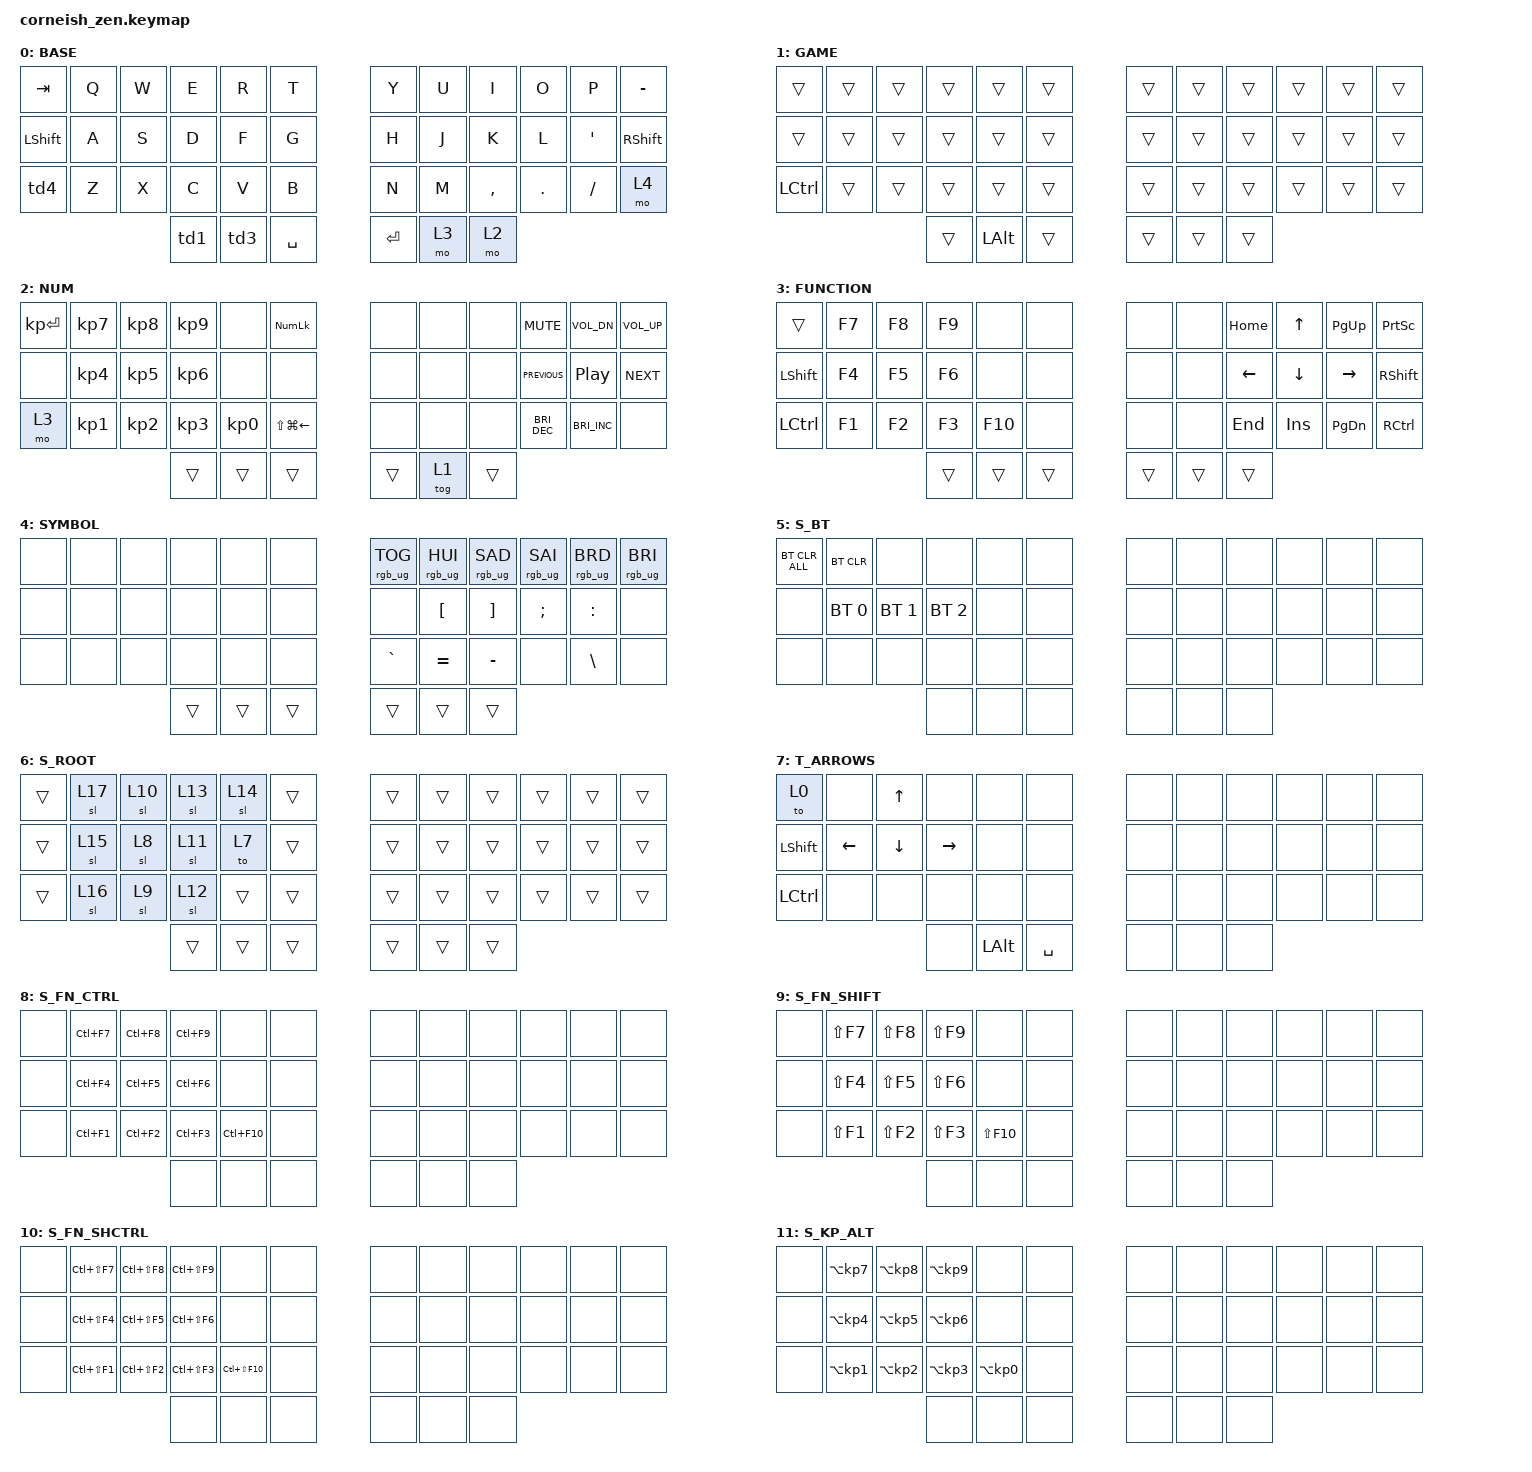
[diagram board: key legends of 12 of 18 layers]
/*
 * Copyright (c) 2020 The ZMK Contributors
 *
 * SPDX-License-Identifier: MIT
 */

#include <behaviors.dtsi>
#include <dt-bindings/zmk/bt.h>
#include <dt-bindings/zmk/keys.h>
#include <dt-bindings/zmk/outputs.h>
#include <dt-bindings/zmk/rgb.h>

/ {
    chosen {
        zmk,matrix_transform = &default_transform;

        // zmk,matrix_transform = &five_column_transform;
    };
};

/ {
    behaviors {
        td0: td0 {
            compatible = "zmk,behavior-tap-dance";
            label = "TD0";
            #binding-cells = <0>;
            bindings = <&kp LEFT_SHIFT>, <&kp CAPSLOCK>;
        };

        td1: td1 {
            compatible = "zmk,behavior-tap-dance";
            label = "TD1";
            #binding-cells = <0>;
            bindings = <&mo 2>, <&kp LEFT_GUI>;
        };

        Mouse_click: Mouse_click {
            compatible = "zmk,behavior-mouse-key-press";
            label = "MOUSE_CLICK";
            #binding-cells = <1>;
        };

        td3: td3 {
            compatible = "zmk,behavior-tap-dance";
            label = "TD3";
            #binding-cells = <0>;
            bindings =
                <&kp LEFT_ALT>,
                <&kp LC(LS(LEFT_ALT))>,
                <&kp LS(LEFT_ALT)>;
        };

        td4: td4 {
            compatible = "zmk,behavior-tap-dance";
            label = "TD4";
            #binding-cells = <0>;
            bindings =
                <&kp LEFT_CONTROL>,
                <&kp LS(LEFT_CONTROL)>,
                <&kp LEFT_SHIFT>;
        };
    };

    combos {
        compatible = "zmk,combos";

        bksp {
            bindings = <&kp BACKSPACE>;
            key-positions = <20 21>;
            layers = <0 2 1 3 4>;
        };

        bi_h_00 {
            bindings = <&kp ESCAPE>;
            key-positions = <1 0>;
            layers = <0 2 3 4 5 1>;
        };

        bi_h_01 {
            bindings = <&kp DELETE>;
            key-positions = <2 1>;
            layers = <0 2 3 4 5>;
        };

        bi_h_02 {
            bindings = <&kp F11>;
            key-positions = <2 3>;
            layers = <0 2 3 4 5>;
        };

        bi_h_03 {
            bindings = <&kp F12>;
            key-positions = <3 4>;
            layers = <0 2 3 4 5>;
        };

        bi_h_04 {
            bindings = <&kp SCROLLLOCK>;
            key-positions = <5 4>;
            layers = <0 2 3 4 5 1>;
        };

        bi_m_01 {
            bindings = <&kp NUMBER_1>;
            key-positions = <13 14>;
            layers = <0 2 3 4 5>;
        };

        bi_m_02 {
            bindings = <&kp NUMBER_2>;
            key-positions = <14 15>;
            layers = <0 2 3 4 5>;
        };

        bi_m_03 {
            bindings = <&kp KP_PLUS>;
            key-positions = <15 16>;
            layers = <0 2 3 4 5>;
        };

        bi_m_04 {
            bindings = <&kp PAUSE_BREAK>;
            key-positions = <16 17>;
            layers = <0 2 3 4 5 1>;
        };

        bi_l_01 {
            bindings = <&kp NUMBER_4>;
            key-positions = <25 26>;
            layers = <0 2 3 4 5>;
        };

        bi_l_02 {
            bindings = <&kp NUMBER_3>;
            key-positions = <26 27>;
            layers = <0 2 3 4 5>;
        };

        bi_l_03 {
            bindings = <&kp KP_MINUS>;
            key-positions = <27 28>;
            layers = <0 2 3 4 5>;
        };

        bi_l_04 {
            bindings = <&kp LC(LS(NUMBER_4))>;
            key-positions = <28 29>;
            layers = <0 2 3 4 5 1>;
        };

        ag_h_01 {
            bindings = <&kp O>;
            key-positions = <13 2>;
            layers = <0 2 3 4 5>;
        };

        ag_h_02 {
            bindings = <&kp P>;
            key-positions = <14 3>;
            layers = <0 2 3 4 5>;
        };

        ag_h_03 {
            bindings = <&none>;
            key-positions = <15 4>;
            layers = <0 2 3 4 5>;
        };

        ag_h_04 {
            bindings = <&none>;
            key-positions = <5 16>;
            layers = <0 2 3 4 5>;
        };

        ag_l_01 {
            bindings = <&kp N9>;
            key-positions = <14 25>;
            layers = <0 2 3 4 5>;
        };

        ag_l_02 {
            bindings = <&kp N7>;
            key-positions = <26 15>;
            layers = <0 2 3 4 5>;
        };

        ag_l_03 {
            bindings = <&kp KP_DIVIDE>;
            key-positions = <16 27>;
            layers = <0 2 3 4 5>;
        };

        ag_l_04 {
            bindings = <&none>;
            key-positions = <17 28>;
            layers = <0 2 3 4 5>;
        };

        gr_h_00 {
            bindings = <&kp CAPSLOCK>;
            key-positions = <0 13>;
            layers = <0 2 3 4 5>;
        };

        gr_h_01 {
            bindings = <&kp Y>;
            key-positions = <1 14>;
            layers = <0 2 3 4 5>;
        };

        gr_h_02 {
            bindings = <&kp I>;
            key-positions = <2 15>;
            layers = <0 2 3 4 5>;
        };

        gr_h_03 {
            bindings = <&kp H>;
            key-positions = <3 16>;
            layers = <0 2 3 4 5>;
        };

        gr_h_04 {
            bindings = <&out OUT_TOG>;
            key-positions = <4 17>;
            layers = <0 2 3 4 5>;
        };

        gr_l_01 {
            bindings = <&kp N8>;
            key-positions = <13 26>;
            layers = <0 2 3 4 5>;
        };

        gr_l_02 {
            bindings = <&kp N0>;
            key-positions = <14 27>;
            layers = <0 2 3 4 5>;
        };

        gr_l_03 {
            bindings = <&kp L>;
            key-positions = <15 28>;
            layers = <0 2 3 4 5>;
        };

        gr_l_04 {
            bindings = <&sl 5>;
            key-positions = <16 29>;
            layers = <0 2 3 4 5>;
        };

        cr_h_01 {
            bindings = <&kp U>;
            key-positions = <13 2 15>;
            layers = <0 2 3 4 5>;
        };

        cr_h_02 {
            bindings = <&kp LG(A)>;
            key-positions = <14 3 16>;
            layers = <0 2 3 4 5>;
        };

        cr_h_03 {
            bindings = <&none>;
            key-positions = <17 4 15>;
            layers = <0 2 3 4 5>;
        };

        cr_l_01 {
            bindings = <&sl 6>;
            key-positions = <27 14 25>;
            layers = <0 2 3 4 5>;
        };

        cr_l_03 {
            bindings = <&none>;
            key-positions = <26 15 28>;
            layers = <0 2 3 4 5>;
        };

        cr_l_04 {
            bindings = <&none>;
            key-positions = <29 16 27>;
            layers = <0 2 3 4 5>;
        };

        tri_h_00 {
            bindings = <&none>;
            key-positions = <0 1 2>;
            layers = <0 2 3 4 5>;
        };

        tri_h_01 {
            bindings = <&kp K>;
            key-positions = <1 2 3>;
            layers = <0 2 3 4 5>;
        };

        tri_h_02 {
            bindings = <&kp J>;
            key-positions = <2 3 4>;
            layers = <0 2 3 4 5>;
        };

        tri_h_03 {
            bindings = <&kp LG(C)>;
            key-positions = <4 5 3>;
            layers = <0 2 3 4 5>;
        };

        tri_m_01 {
            bindings = <&kp N>;
            key-positions = <13 14 15>;
            layers = <0 2 3 4 5>;
        };

        tri_m_02 {
            bindings = <&kp M>;
            key-positions = <14 15 16>;
            layers = <0 2 3 4 5>;
        };

        tri_m_03 {
            bindings = <&none>;
            key-positions = <15 16 17>;
            layers = <0 2 3 4 5>;
        };

        tri_l_01 {
            bindings = <&kp COMMA>;
            key-positions = <25 26 27>;
            layers = <0 2 3 4 5>;
        };

        tri_l_02 {
            bindings = <&kp PERIOD>;
            key-positions = <26 27 28>;
            layers = <0 2 3 4 5>;
        };

        tri_l_03 {
            bindings = <&none>;
            key-positions = <27 28 29>;
            layers = <0 2 3 4 5>;
        };

        g_bi_h_00 {
            bindings = <&none>;
            key-positions = <0 2>;
            layers = <0 2 3 4 5>;
        };

        g_bi_h_01 {
            bindings = <&none>;
            key-positions = <3 1>;
            layers = <0 2 3 4 5>;
        };

        g_bi_h_03 {
            bindings = <&none>;
            key-positions = <4 2>;
            layers = <0 2 3 4 5>;
        };

        g_bi_h_04 {
            bindings = <&none>;
            key-positions = <5 3>;
            layers = <0 2 3 4 5>;
        };

        g_bi_m_01 {
            bindings = <&kp N5>;
            key-positions = <13 15>;
            layers = <0 2 3 4 5>;
        };

        g_bi_m_02 {
            bindings = <&kp KP_MULTIPLY>;
            key-positions = <16 14>;
            layers = <0 2 3 4 5>;
        };

        g_bi_m_03 {
            bindings = <&none>;
            key-positions = <17 15>;
            layers = <0 2 3 4 5>;
        };

        g_bi_l_01 {
            bindings = <&kp NUMBER_6>;
            key-positions = <25 27>;
            layers = <0 2 3 4 5>;
        };

        g_bi_l_02 {
            bindings = <&kp KP_DOT>;
            key-positions = <28 26>;
            layers = <0 2 3 4 5>;
        };

        g_bi_l_03 {
            bindings = <&none>;
            key-positions = <29 27>;
            layers = <0 2 3 4 5>;
        };

        qua_ag_l_01 {
            bindings = <&kp LG(UP_ARROW)>;
            key-positions = <15 25 26 16>;
            layers = <0 2 3 4 5>;
        };

        arc_ag_l_01 {
            bindings = <&kp LG(LEFT_ARROW)>;
            key-positions = <26 15 25>;
            layers = <0 2 3 4 5>;
        };

        spike_l_01 {
            bindings = <&kp LG(RIGHT)>;
            key-positions = <26 15 25 28>;
            layers = <0 2 3 4 5>;
        };

        arc_gr_inv_l_01 {
            bindings = <&kp MINUS>;
            key-positions = <13 14 27>;
            layers = <0 2 3 4 5>;
        };

        arc_gr_inv_l_02 {
            bindings = <&kp SEMICOLON>;
            key-positions = <15 14 28>;
            layers = <0 2 3 4 5>;
        };
    };

    keymap {
        compatible = "zmk,keymap";

        base {
            display-name = "BASE";
            bindings = <
&kp TAB         &kp Q  &kp W  &kp E  &kp R  &kp T        &kp Y      &kp U  &kp I      &kp O    &kp P      &kp MINUS
&kp LEFT_SHIFT  &kp A  &kp S  &kp D  &kp F  &kp G        &kp H      &kp J  &kp K      &kp L    &kp APOS   &kp RSHFT
&td4            &kp Z  &kp X  &kp C  &kp V  &kp B        &kp N      &kp M  &kp COMMA  &kp DOT  &kp SLASH  &mo 4
                              &td1   &td3   &kp SPACE    &kp ENTER  &mo 3  &mo 2
            >;
        };

        gaming {
            bindings = <
&trans     &trans  &trans  &trans  &trans        &trans    &trans  &trans  &trans  &trans  &trans  &trans
&trans     &trans  &trans  &trans  &trans        &trans    &trans  &trans  &trans  &trans  &trans  &trans
&kp LCTRL  &trans  &trans  &trans  &trans        &trans    &trans  &trans  &trans  &trans  &trans  &trans
                           &trans  &kp LEFT_ALT  &trans    &trans  &trans  &trans
            >;

            label = "GAME";
        };

        KP_NUM_MEDIA {
            display-name = "NUM";
            bindings = <
&kp KP_ENTER  &kp KP_NUMBER_7  &kp KP_NUMBER_8  &kp KP_N9        &none      &kp KP_NUM          &none   &none   &none   &kp C_MUTE            &kp C_VOL_DN          &kp C_VOL_UP
&none         &kp KP_NUMBER_4  &kp KP_NUMBER_5  &kp KP_N6        &none      &none               &none   &none   &none   &kp C_PREVIOUS        &kp C_PLAY_PAUSE      &kp C_NEXT
&mo 3         &kp KP_NUMBER_1  &kp KP_NUMBER_2  &kp KP_NUMBER_3  &kp KP_N0  &kp LS(LG(LEFT))    &none   &none   &none   &kp C_BRIGHTNESS_DEC  &kp C_BRIGHTNESS_INC  &none
                                                &trans           &trans     &trans              &trans  &tog 1  &trans
            >;
        };

        FN_NAV {
            display-name = "FUNCTION";
            bindings = <
&trans          &kp F7  &kp F8  &kp F9  &none    &none     &none   &none   &kp HOME        &kp UP_ARROW    &kp PAGE_UP    &kp PRINTSCREEN
&kp LEFT_SHIFT  &kp F4  &kp F5  &kp F6  &none    &none     &none   &none   &kp LEFT_ARROW  &kp DOWN_ARROW  &kp RIGHT      &kp RIGHT_SHIFT
&kp LCTRL       &kp F1  &kp F2  &kp F3  &kp F10  &none     &none   &none   &kp END         &kp INSERT      &kp PAGE_DOWN  &kp RIGHT_CONTROL
                                &trans  &trans   &trans    &trans  &trans  &trans
            >;
        };

        SYM_RGB {
            bindings = <
&none  &none  &none  &none   &none   &none     &rgb_ug RGB_TOG  &rgb_ug RGB_HUI  &rgb_ug RGB_SAD  &rgb_ug RGB_SAI  &rgb_ug RGB_BRD  &rgb_ug RGB_BRI
&none  &none  &none  &none   &none   &none     &none            &kp LBKT         &kp RBKT         &kp SEMICOLON    &kp COLON        &none
&none  &none  &none  &none   &none   &none     &kp GRAVE        &kp EQUAL        &kp MINUS        &none            &kp BSLH         &none
                     &trans  &trans  &trans    &trans           &trans           &trans
            >;

            label = "SYMBOL";
        };

        S_BT {
            bindings = <
&bt BT_CLR_ALL  &bt BT_CLR    &none         &none         &none  &none    &none  &none  &none  &none  &none  &none
&none           &bt BT_SEL 0  &bt BT_SEL 1  &bt BT_SEL 2  &none  &none    &none  &none  &none  &none  &none  &none
&none           &none         &none         &none         &none  &none    &none  &none  &none  &none  &none  &none
                                            &none         &none  &none    &none  &none  &none
            >;
        };

        S_ROOT {
            bindings = <
&trans  &sl 17  &sl 10  &sl 13  &sl 14  &trans    &trans  &trans  &trans  &trans  &trans  &trans
&trans  &sl 15  &sl 8   &sl 11  &to 7   &trans    &trans  &trans  &trans  &trans  &trans  &trans
&trans  &sl 16  &sl 9   &sl 12  &trans  &trans    &trans  &trans  &trans  &trans  &trans  &trans
                        &trans  &trans  &trans    &trans  &trans  &trans
            >;
        };

        T_ARROWS {
            bindings = <
&to 0           &none           &kp UP_ARROW    &none            &none         &none        &none  &none  &none  &none  &none  &none
&kp LEFT_SHIFT  &kp LEFT_ARROW  &kp DOWN_ARROW  &kp RIGHT_ARROW  &none         &none        &none  &none  &none  &none  &none  &none
&kp LCTRL       &none           &none           &none            &none         &none        &none  &none  &none  &none  &none  &none
                                                &none            &kp LEFT_ALT  &kp SPACE    &none  &none  &none
            >;
        };

        S_FN_CTRL {
            bindings = <
&none  &kp LC(F7)  &kp LC(F8)  &kp LC(F9)  &none        &none    &none  &none  &none  &none  &none  &none
&none  &kp LC(F4)  &kp LC(F5)  &kp LC(F6)  &none        &none    &none  &none  &none  &none  &none  &none
&none  &kp LC(F1)  &kp LC(F2)  &kp LC(F3)  &kp LC(F10)  &none    &none  &none  &none  &none  &none  &none
                               &none       &none        &none    &none  &none  &none
            >;
        };

        S_FN_SHIFT {
            bindings = <
&none  &kp LS(F7)  &kp LS(F8)  &kp LS(F9)  &none        &none    &none  &none  &none  &none  &none  &none
&none  &kp LS(F4)  &kp LS(F5)  &kp LS(F6)  &none        &none    &none  &none  &none  &none  &none  &none
&none  &kp LS(F1)  &kp LS(F2)  &kp LS(F3)  &kp LS(F10)  &none    &none  &none  &none  &none  &none  &none
                               &none       &none        &none    &none  &none  &none
            >;
        };

        S_FN_SHCTRL {
            bindings = <
&none  &kp LC(LS(F7))  &kp LC(LS(F8))  &kp LC(LS(F9))  &none            &none    &none  &none  &none  &none  &none  &none
&none  &kp LC(LS(F4))  &kp LC(LS(F5))  &kp LC(LS(F6))  &none            &none    &none  &none  &none  &none  &none  &none
&none  &kp LC(LS(F1))  &kp LC(LS(F2))  &kp LC(LS(F3))  &kp LC(LS(F10))  &none    &none  &none  &none  &none  &none  &none
                                       &none           &none            &none    &none  &none  &none
            >;
        };

        S_KP_ALT {
            bindings = <
&none  &kp LA(KP_NUMBER_7)  &kp LA(KP_NUMBER_8)  &kp LA(KP_NUMBER_9)  &none                &none    &none  &none  &none  &none  &none  &none
&none  &kp LA(KP_NUMBER_4)  &kp LA(KP_NUMBER_5)  &kp LA(KP_NUMBER_6)  &none                &none    &none  &none  &none  &none  &none  &none
&none  &kp LA(KP_NUMBER_1)  &kp LA(KP_NUMBER_2)  &kp LA(KP_NUMBER_3)  &kp LA(KP_NUMBER_0)  &none    &none  &none  &none  &none  &none  &none
                                                 &none                &none                &none    &none  &none  &none
            >;
        };

        S_KP_SHIFT {
            bindings = <
&none  &kp LS(KP_NUMBER_7)  &kp LS(KP_NUMBER_8)  &kp LS(KP_NUMBER_9)  &none                &none    &none  &none  &none  &none  &none  &none
&none  &kp LS(KP_NUMBER_4)  &kp LS(KP_NUMBER_5)  &kp LS(KP_NUMBER_6)  &none                &none    &none  &none  &none  &none  &none  &none
&none  &kp LS(KP_NUMBER_1)  &kp LS(KP_NUMBER_2)  &kp LS(KP_NUMBER_3)  &kp LS(KP_NUMBER_0)  &none    &none  &none  &none  &none  &none  &none
                                                 &none                &none                &none    &none  &none  &none
            >;
        };

        S_KP_SHALT {
            bindings = <
&none  &kp LA(LS(KP_NUMBER_7))  &kp LA(LS(KP_NUMBER_8))  &kp LA(LS(KP_NUMBER_9))  &none                    &none    &none  &none  &none  &none  &none  &none
&none  &kp LA(LS(KP_NUMBER_4))  &kp LA(LS(KP_NUMBER_5))  &kp LA(LS(KP_NUMBER_6))  &none                    &none    &none  &none  &none  &none  &none  &none
&none  &kp LA(LS(KP_NUMBER_1))  &kp LA(LS(KP_NUMBER_2))  &kp LA(LS(KP_NUMBER_3))  &kp LA(LS(KP_NUMBER_0))  &none    &none  &none  &none  &none  &none  &none
                                                         &none                    &none                    &none    &none  &none  &none
            >;
        };

        S_L_ALPHAS_SCHTRL {
            bindings = <
&trans  &kp LS(LC(Q))  &kp LS(LC(W))  &kp LS(LC(E))  &kp LS(LC(R))  &kp LS(LC(T))    &trans  &trans  &trans  &trans  &trans  &trans
&trans  &kp LS(LC(A))  &kp LS(LC(S))  &kp LS(LC(D))  &kp LS(LC(F))  &kp LS(LC(G))    &trans  &trans  &trans  &trans  &trans  &trans
&trans  &kp LS(LC(Z))  &kp LS(LC(X))  &kp LS(LC(C))  &kp LS(LC(V))  &kp LS(LC(B))    &trans  &trans  &trans  &trans  &trans  &trans
                                      &trans         &trans         &trans           &trans  &trans  &trans
            >;
        };

        S_R_ALPHAS {
            bindings = <
&none  &kp Y  &kp U  &kp I  &kp O  &kp P    &none  &none  &none  &none  &none  &none
&none  &kp H  &kp J  &kp K  &kp L  &none    &none  &none  &none  &none  &none  &none
&none  &kp N  &kp M  &none  &none  &none    &none  &none  &none  &none  &none  &none
                     &none  &none  &none    &none  &none  &none
            >;
        };

        S_R_ALPHAS_SHIFT {
            bindings = <
&none  &kp LS(Y)  &kp LS(U)  &kp LS(I)  &kp LS(O)  &kp LS(P)    &none  &none  &none  &none  &none  &none
&none  &kp LS(H)  &kp LS(J)  &kp LS(K)  &kp LS(L)  &none        &none  &none  &none  &none  &none  &none
&none  &kp LS(N)  &kp LS(M)  &none      &none      &none        &none  &none  &none  &none  &none  &none
                             &none      &none      &none        &none  &none  &none
            >;
        };

        S_R_ALPHAS_SHCTRL {
            bindings = <
&none  &kp LS(LC(Y))  &kp LS(LC(U))  &kp LS(LC(I))  &kp LS(LC(O))  &kp LS(LC(P))    &none  &none  &none  &none  &none  &none
&none  &kp LS(LC(H))  &kp LS(LC(J))  &kp LS(LC(K))  &kp LS(LC(L))  &none            &none  &none  &none  &none  &none  &none
&none  &kp LS(LC(N))  &kp LS(LC(M))  &none          &none          &none            &none  &none  &none  &none  &none  &none
                                     &none          &none          &none            &none  &none  &none
            >;
        };
    };

    conditional_layers { compatible = "zmk,conditional-layers"; };
};
